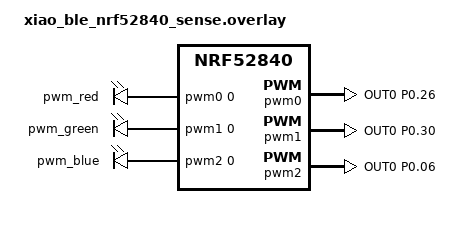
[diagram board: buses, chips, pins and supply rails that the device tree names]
&pwm0 {
	status = "okay";
	pinctrl-0 = <&pwm_red_default>;
	pinctrl-1 = <&pwm_red_sleep>;
	pinctrl-names = "default", "sleep";
};

&pwm1 {
	status = "okay";
	pinctrl-0 = <&pwm_green_default>;
	pinctrl-1 = <&pwm_green_sleep>;
	pinctrl-names = "default", "sleep";
};

&pwm2 {
	status = "okay";
	pinctrl-0 = <&pwm_blue_default>;
	pinctrl-1 = <&pwm_blue_sleep>;
	pinctrl-names = "default", "sleep";
};

/delete-node/ &pwm_led0;

&pinctrl {
	pwm_red_default: pwm_red_default {
		group1 {
			psels = <NRF_PSEL(PWM_OUT0, 0, 26)>;  //Led Vermelho
			nordic,invert;
		};
	};

	pwm_red_sleep: pwm_red_sleep {
		group1 {
			psels = <NRF_PSEL(PWM_OUT0, 0, 26)>; //Led Vermelho
			low-power-enable;
		};
	};

    pwm_green_default: pwm_green_default {
		group1 {
			psels = <NRF_PSEL(PWM_OUT0, 0, 30)>;  //Led Verde
			nordic,invert;
		};
	};

	pwm_green_sleep: pwm_green_sleep {
		group1 {
			psels = <NRF_PSEL(PWM_OUT0, 0, 30)>; //Led Verde
			low-power-enable;
		};
	};

    pwm_blue_default: pwm_blue_default {
		group1 {
			psels = <NRF_PSEL(PWM_OUT0, 0, 06)>;  //Led Azul
			nordic,invert;
		};
	};

	pwm_blue_sleep: pwm_blue_sleep {
		group1 {
			psels = <NRF_PSEL(PWM_OUT0, 0, 06)>; //Led Azul
			low-power-enable;
		};
	};

};
/ {
    aliases {
        /delete-property/ pwm-led0;
        pwm-red = &pwm_red;
        pwm-green = &pwm_green;
        pwm-blue = &pwm_blue;
    };

    pwmleds {
        compatible = "pwm-leds";
        pwm_red: pwm_red {
            pwms = <&pwm0 0 PWM_MSEC(20) PWM_POLARITY_INVERTED>;
        };

        pwm_green: pwm_green {
            pwms = <&pwm1 0 PWM_MSEC(20) PWM_POLARITY_INVERTED>;
        };

        pwm_blue: pwm_blue {
            pwms = <&pwm2 0 PWM_MSEC(20) PWM_POLARITY_INVERTED>;
        };
    };

};

